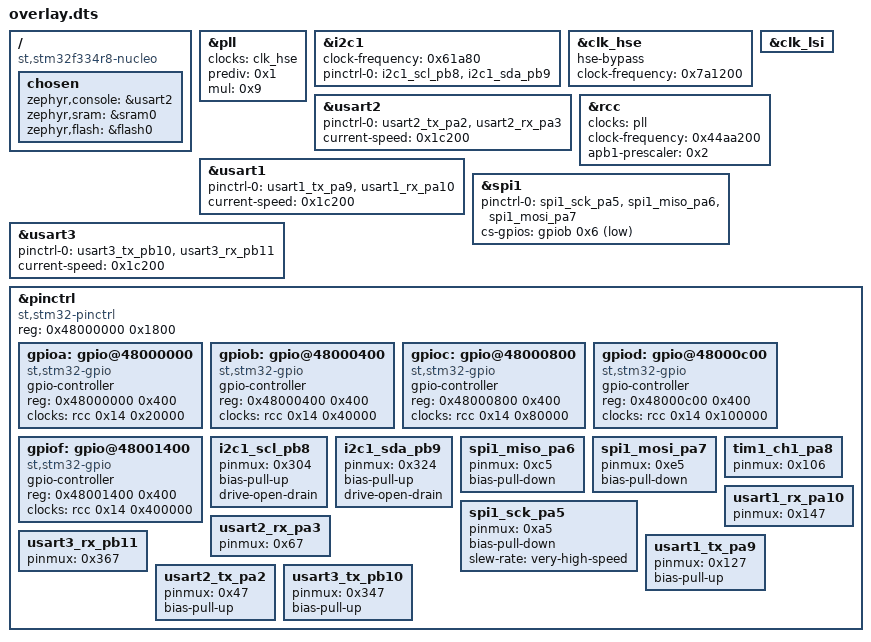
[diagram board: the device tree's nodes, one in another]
/ {
	compatible = "st,stm32f334r8-nucleo";
	chosen {
		zephyr,console = &usart2;
		zephyr,sram = &sram0;
		zephyr,flash = &flash0;
	};
};
&pll{
	status = "okay";
	clocks = < &clk_hse >;
	prediv = < 0x1 >;
	mul = < 0x9 >;
};
&i2c1{
	clock-frequency = < 0x61a80 >;
	status = "okay";
	pinctrl-0 = < &i2c1_scl_pb8 &i2c1_sda_pb9 >;
	pinctrl-names = "default";
};
&clk_hse{
	status = "okay";
	hse-bypass;
	clock-frequency = < 0x7a1200 >;
};
&usart2{
	status = "okay";
	pinctrl-0 = < &usart2_tx_pa2 &usart2_rx_pa3 >;
	pinctrl-names = "default";
	current-speed = < 0x1c200 >;
};
&clk_lsi{
	status = "okay";
};
&rcc{
	clocks = < &pll >;
	clock-frequency = < 0x44aa200 >;
	apb1-prescaler = < 0x2 >;
};
&usart1{
	status = "okay";
	pinctrl-0 = < &usart1_tx_pa9 &usart1_rx_pa10 >;
	pinctrl-names = "default";
	current-speed = < 0x1c200 >;
};
&spi1{
	status = "okay";
	pinctrl-0 = < &spi1_sck_pa5 &spi1_miso_pa6 &spi1_mosi_pa7 >;
	pinctrl-names = "default";
	cs-gpios = < &gpiob 0x6 0x11 >;
};
&usart3{
	pinctrl-0 = < &usart3_tx_pb10 &usart3_rx_pb11 >;
	pinctrl-names = "default";
	current-speed = < 0x1c200 >;
};
&pinctrl{
	compatible = "st,stm32-pinctrl";
	#address-cells = < 0x1 >;
	#size-cells = < 0x1 >;
	reg = < 0x48000000 0x1800 >;
	gpioa: gpio@48000000 {
		compatible = "st,stm32-gpio";
		gpio-controller;
		#gpio-cells = < 0x2 >;
		reg = < 0x48000000 0x400 >;
		clocks = < &rcc 0x14 0x20000 >;
	};
	gpiob: gpio@48000400 {
		compatible = "st,stm32-gpio";
		gpio-controller;
		#gpio-cells = < 0x2 >;
		reg = < 0x48000400 0x400 >;
		clocks = < &rcc 0x14 0x40000 >;
	};
	gpioc: gpio@48000800 {
		compatible = "st,stm32-gpio";
		gpio-controller;
		#gpio-cells = < 0x2 >;
		reg = < 0x48000800 0x400 >;
		clocks = < &rcc 0x14 0x80000 >;
	};
	gpiod: gpio@48000c00 {
		compatible = "st,stm32-gpio";
		gpio-controller;
		#gpio-cells = < 0x2 >;
		reg = < 0x48000c00 0x400 >;
		clocks = < &rcc 0x14 0x100000 >;
	};
	gpiof: gpio@48001400 {
		compatible = "st,stm32-gpio";
		gpio-controller;
		#gpio-cells = < 0x2 >;
		reg = < 0x48001400 0x400 >;
		clocks = < &rcc 0x14 0x400000 >;
	};
	i2c1_scl_pb8: i2c1_scl_pb8 {
		pinmux = < 0x304 >;
		bias-pull-up;
		drive-open-drain;
	};
	i2c1_sda_pb9: i2c1_sda_pb9 {
		pinmux = < 0x324 >;
		bias-pull-up;
		drive-open-drain;
	};
	spi1_miso_pa6: spi1_miso_pa6 {
		pinmux = < 0xc5 >;
		bias-pull-down;
	};
	spi1_mosi_pa7: spi1_mosi_pa7 {
		pinmux = < 0xe5 >;
		bias-pull-down;
	};
	spi1_sck_pa5: spi1_sck_pa5 {
		pinmux = < 0xa5 >;
		bias-pull-down;
		slew-rate = "very-high-speed";
	};
	tim1_ch1_pa8: tim1_ch1_pa8 {
		pinmux = < 0x106 >;
	};
	usart1_rx_pa10: usart1_rx_pa10 {
		pinmux = < 0x147 >;
	};
	usart2_rx_pa3: usart2_rx_pa3 {
		pinmux = < 0x67 >;
	};
	usart3_rx_pb11: usart3_rx_pb11 {
		pinmux = < 0x367 >;
	};
	usart1_tx_pa9: usart1_tx_pa9 {
		pinmux = < 0x127 >;
		bias-pull-up;
	};
	usart2_tx_pa2: usart2_tx_pa2 {
		pinmux = < 0x47 >;
		bias-pull-up;
	};
	usart3_tx_pb10: usart3_tx_pb10 {
		pinmux = < 0x347 >;
		bias-pull-up;
	};
};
